# EFM32GG11B820F2048IQ100 register map
File version: 4.0.0
CPU: CM4 r0p1, little endian, MPU, FPU, 3 interrupt priority bits
Registers are 32-bit, read-write, reset 0x0 unless marked. A register's access mark holds for its fields unless they carry their own. Offsets are from the block's base; [hi:lo] are bit positions; 'fields as' and 'values as' point back to an identical list.

## RMU
Base 0x400E5000
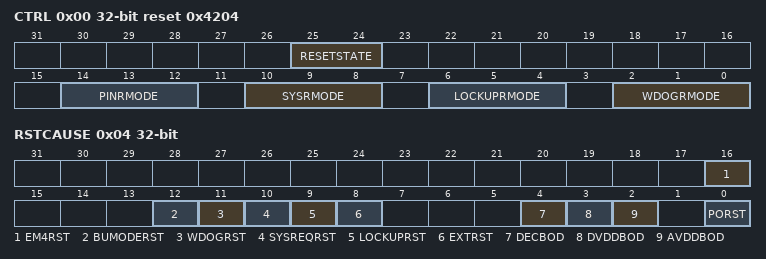
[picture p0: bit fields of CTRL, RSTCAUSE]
0x00 CTRL reset 0x4204 — Control Register
  [25:24] RESETSTATE — System Software Reset State
  [14:12] PINRMODE — PIN Reset Mode
    0=DISABLED (Reset request is blocked.); 1=LIMITED (The CRYOTIMER, DEBUGGER, RTCC, are not reset.); 2=EXTENDED (The CRYOTIMER, DEBUGGER are not reset. RTCC is reset.); 4=FULL (The entire device is reset except some EMU and RMU registers.)
  [10:8] SYSRMODE — Core Sysreset Reset Mode
    values as PINRMODE
  [6:4] LOCKUPRMODE — Core LOCKUP Reset Mode
    values as PINRMODE
  [2:0] WDOGRMODE — WDOG Reset Mode
    0=DISABLED (Reset request is blocked. This disable bit is redundant with enable/disable bit in WDOG); 1=LIMITED (The CRYOTIMER, DEBUGGER, RTCC, are not reset.); 2=EXTENDED (The CRYOTIMER, DEBUGGER are not reset. RTCC is reset.); 4=FULL (The entire device is reset except some EMU and RMU registers.)
0x04 RSTCAUSE ro — Reset Cause Register
  [16] EM4RST — EM4 Reset
  [12] BUMODERST — Backup Mode Reset
  [11] WDOGRST — Watchdog Reset
  [10] SYSREQRST — System Request Reset
  [9] LOCKUPRST — LOCKUP Reset
  [8] EXTRST — External Pin Reset
  [4] DECBOD — Brown Out Detector Decouple Domain Reset
  [3] DVDDBOD — Brown Out Detector DVDD Reset
  [2] AVDDBOD — Brown Out Detector AVDD Reset
  [0] PORST — Power on Reset
0x08 CMD wo — Command Register
  [0] RCCLR — Reset Cause Clear
0x0C RST reset not defined — Reset Control Register
0x10 LOCK — Configuration Lock Register
  [15:0] LOCKKEY — Configuration Lock Key
    0=UNLOCKED; 1=LOCKED

## FPUEH
Base 0x40001000
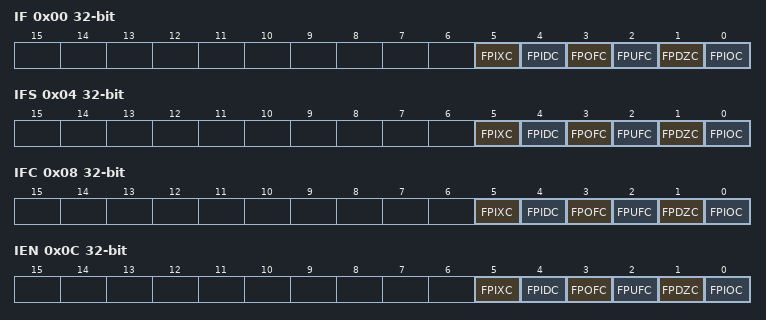
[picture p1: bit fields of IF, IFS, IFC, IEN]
0x00 IF ro — Interrupt Flag Register
  [5] FPIXC — FPU inexact exception
  [4] FPIDC — FPU input denormal exception
  [3] FPOFC — FPU overflow exception
  [2] FPUFC — FPU underflow exception
  [1] FPDZC — FPU divide-by-zero exception
  [0] FPIOC — FPU invalid operation
0x04 IFS wo — Interrupt Flag Set Register
  [5] FPIXC — Set FPIXC Interrupt Flag
  [4] FPIDC — Set FPIDC Interrupt Flag
  [3] FPOFC — Set FPOFC Interrupt Flag
  [2] FPUFC — Set FPUFC Interrupt Flag
  [1] FPDZC — Set FPDZC Interrupt Flag
  [0] FPIOC — Set FPIOC Interrupt Flag
0x08 IFC wo — Interrupt Flag Clear Register
  [5] FPIXC — Clear FPIXC Interrupt Flag
  [4] FPIDC — Clear FPIDC Interrupt Flag
  [3] FPOFC — Clear FPOFC Interrupt Flag
  [2] FPUFC — Clear FPUFC Interrupt Flag
  [1] FPDZC — Clear FPDZC Interrupt Flag
  [0] FPIOC — Clear FPIOC Interrupt Flag
0x0C IEN — Interrupt Enable Register
  [5] FPIXC — FPIXC Interrupt Enable
  [4] FPIDC — FPIDC Interrupt Enable
  [3] FPOFC — FPOFC Interrupt Enable
  [2] FPUFC — FPUFC Interrupt Enable
  [1] FPDZC — FPDZC Interrupt Enable
  [0] FPIOC — FPIOC Interrupt Enable

## GPCRC
Base 0x4001C000
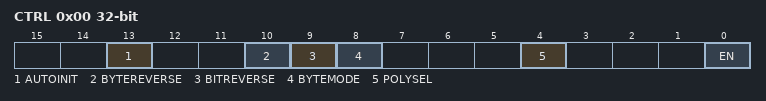
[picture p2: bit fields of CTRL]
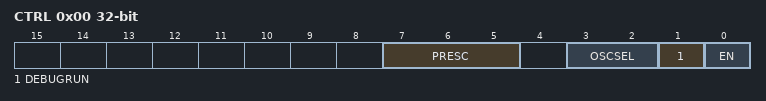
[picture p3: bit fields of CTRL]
0x00 CTRL — Control Register
  [13] AUTOINIT — Auto Init Enable
  [10] BYTEREVERSE — Byte Reverse Mode
  [9] BITREVERSE — Byte-level Bit Reverse Enable
  [8] BYTEMODE — Byte Mode Enable
  [4] POLYSEL — Polynomial Select
  [0] EN — CRC Functionality Enable
0x04 CMD wo — Command Register
  [0] INIT — Initialization Enable
0x08 INIT — CRC Init Value
  [31:0] INIT — CRC Initialization Value
0x0C POLY — CRC Polynomial Value
  [15:0] POLY
0x10 INPUTDATA — Input 32-bit Data Register
  [31:0] INPUTDATA — Input Data for 32-bit
0x14 INPUTDATAHWORD — Input 16-bit Data Register
  [15:0] INPUTDATAHWORD — Input Data for 16-bit
0x18 INPUTDATABYTE — Input 8-bit Data Register
  [7:0] INPUTDATABYTE — Input Data for 8-bit
0x1C DATA ro — CRC Data Register
0x20 DATAREV ro — CRC Data Reverse Register
  [31:0] DATAREV — Data Reverse Value
0x24 DATABYTEREV ro — CRC Data Byte Reverse Register
  [31:0] DATABYTEREV — Data Byte Reverse Value

## CRYOTIMER
Base 0x4008F000
0x00 CTRL — Control Register
  [7:5] PRESC — Prescaler Setting
    0=DIV1 (LF Oscillator frequency undivided); 1=DIV2 (LF Oscillator frequency divided by 2); 2=DIV4 (LF Oscillator frequency divided by 4); 3=DIV8 (LF Oscillator frequency divided by 8); 4=DIV16 (LF Oscillator frequency divided by 16); 5=DIV32 (LF Oscillator frequency divided by 32); 6=DIV64 (LF Oscillator frequency divided by 64); 7=DIV128 (LF Oscillator frequency divided by 128)
  [3:2] OSCSEL — Select Low Frequency Oscillator
    0=DISABLED (Output is driven low); 1=LFRCO (Select Low Frequency RC Oscillator); 2=LFXO (Select Low Frequency Crystal Oscillator); 3=ULFRCO (Select Ultra Low Frequency RC Oscillator)
  [1] DEBUGRUN — Debug Mode Run Enable
  [0] EN — Enable CRYOTIMER
0x04 PERIODSEL reset 0x20 — Interrupt Duration
  [5:0] PERIODSEL — Interrupts/Wakeup Events Period Setting
0x08 CNT ro — Counter Value
0x0C EM4WUEN — Wake Up Enable
  [0] EM4WU — EM4 Wake-up Enable
0x10 IF ro — Interrupt Flag Register
  [0] PERIOD — Wakeup Event/Interrupt
0x14 IFS wo — Interrupt Flag Set Register
  [0] PERIOD — Set PERIOD Interrupt Flag
0x18 IFC wo — Interrupt Flag Clear Register
  [0] PERIOD — Clear PERIOD Interrupt Flag
0x1C IEN — Interrupt Enable Register
  [0] PERIOD — PERIOD Interrupt Enable

## Notices in the file
# License
Copyright 2021 Silicon Laboratories Inc. www.silabs.com
SPDX-License-Identifier: Zlib
The licensor of this software is Silicon Laboratories Inc.
This software is provided 'as-is', without any express or implied
warranty. In no event will the authors be held liable for any damages
arising from the use of this software.
Permission is granted to anyone to use this software for any purpose,
including commercial applications, and to alter it and redistribute it
freely, subject to the following restrictions:
1. The origin of this software must not be misrepresented; you must not
claim that you wrote the original software. If you use this software
in a product, an acknowledgment in the product documentation would be
appreciated but is not required.
2. Altered source versions must be plainly marked as such, and must not be
misrepresented as being the original software.
3. This notice may not be removed or altered from any source distribution.
